AUTOSAR XML (schema 4-0-3)
package /ComponentTypes
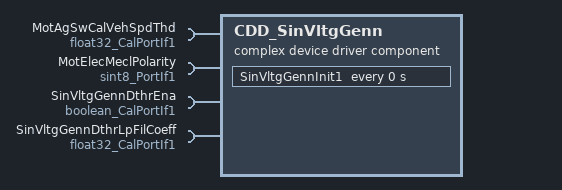
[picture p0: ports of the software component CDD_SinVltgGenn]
  complex device driver sw component type CDD_SinVltgGenn
    4 x require port:
      MotAgSwCalVehSpdThd: parameter-require-com-spec{init-value=3, parameter=Val}, required-interface=float32_CalPortIf1
      MotElecMeclPolarity: nonqueued-receiver-com-spec{data-element=Val, filter=data-filter-type=ALWAYS, init-value=1}, required-interface=sint8_PortIf1
      SinVltgGennDthrEna: parameter-require-com-spec{init-value=1, parameter=Logl}, required-interface=boolean_CalPortIf1
      SinVltgGennDthrLpFilCoeff: parameter-require-com-spec{init-value=0.625, parameter=Val}, required-interface=float32_CalPortIf1
    behavior CDD_SinVltgGenn_InternalBehavior
      ar-typed-per-instance-memorys:
        10 x data, all with sw-calibration-access=READ-ONLY:
          Fil1OutpPrev: type=float32
          Fil2OutpPrev: type=float32
          PhaDptOffsA: type=float32
          PhaDptOffsB: type=float32
          PhaDptOffsC: type=float32
          PhaOnTiSumAPrev: type=uint32
          PhaOnTiSumBPrev: type=uint32
          PhaOnTiSumCPrev: type=uint32
          PwmPerdRng: type=uint32
          RndNrPrev: type=float32
      timing event SinVltgGenn_InitEvent: start-on-event=SinVltgGennInit1, period=0
      runnable SinVltgGennInit1
        data-receive-point-by-arguments:
          access REC_MotElecMeclPolarity_Val_1: accessed-variable=MotElecMeclPolarity.Val
  swc implementation CDD_SinVltgGenn_Implementation: behavior=CDD_SinVltgGenn_InternalBehavior
    code-descriptors:
      code Default: artifact-descriptors=autosar-engineering-object={short-label=Default, category=SWSRC}
